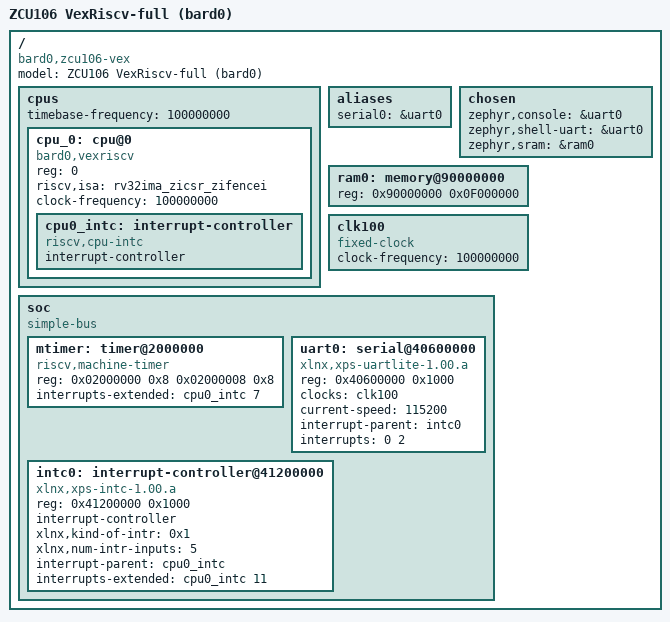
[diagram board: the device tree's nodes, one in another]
// SPDX-License-Identifier: Apache-2.0
// Copyright (c) 2026 Leonardo Capossio - bard0 design
//
// Zephyr DTS for the ZCU106 VexRiscv-full shell (hardware built by
// hardware/scripts/build_zcu106.py --variant vex). Same CPU complex, clock
// (100 MHz) and memory map as the Arty A7 Vex shell; the 256 MiB window at
// 0x9000_0000 is in PS DDR4 instead of DDR3:
//   0x9000_0000  240 MiB, mostly inside the Vex D-cache aperture: Zephyr
//   0x9F00_0000  16 MiB, outside it: DMA descriptors, frame buffers and
//                the host page (the app overlay places them)

/dts-v1/;

/ {
	#address-cells = <1>;
	#size-cells = <1>;
	model = "ZCU106 VexRiscv-full (bard0)";
	compatible = "bard0,zcu106-vex";

	cpus {
		#address-cells = <1>;
		#size-cells = <0>;
		timebase-frequency = <100000000>;

		cpu_0: cpu@0 {
			compatible = "bard0,vexriscv", "riscv";
			device_type = "cpu";
			reg = <0>;
			riscv,isa = "rv32ima_zicsr_zifencei";
			clock-frequency = <100000000>;

			cpu0_intc: interrupt-controller {
				compatible = "riscv,cpu-intc";
				interrupt-controller;
				#interrupt-cells = <1>;
			};
		};
	};

	aliases {
		serial0 = &uart0;
	};

	chosen {
		zephyr,console = &uart0;
		zephyr,shell-uart = &uart0;
		zephyr,sram = &ram0;
	};

	// PS DDR4, 240 MiB usable (0x9000_0000 .. 0x9EFF_FFFF, as on the
	// Arty). fcapz stages the Zephyr image here; the boot ROM at 0x0 jumps
	// in.
	ram0: memory@90000000 {
		device_type = "memory";
		reg = <0x90000000 0x0F000000>;
	};

	clk100: clk100 {
		compatible = "fixed-clock";
		#clock-cells = <0>;
		clock-frequency = <100000000>;
	};

	soc {
		#address-cells = <1>;
		#size-cells = <1>;
		compatible = "simple-bus";
		ranges;

		// riscv_mtimer.v: mtime at +0, mtimecmp at +8
		mtimer: timer@2000000 {
			compatible = "riscv,machine-timer";
			reg = <0x02000000 0x8 0x02000008 0x8>;
			reg-names = "mtime", "mtimecmp";
			interrupts-extended = <&cpu0_intc 7>;
		};

		// AXI UARTLite on the CP2108's PL channel. IRQ 0 on the axi_intc.
		uart0: serial@40600000 {
			compatible = "xlnx,xps-uartlite-1.00.a";
			reg = <0x40600000 0x1000>;
			clocks = <&clk100>;
			current-speed = <115200>;
			interrupt-parent = <&intc0>;
			interrupts = <0 2>;
			status = "okay";
		};

		// AXI INTC, dispatching to VexRiscv's M-mode external interrupt.
		// Inputs: 0 uart0 (edge), 1 PCS/PMA status GPIO, 2 axi_dma mm2s,
		// 3 axi_dma s2mm, 4 emaczero.
		intc0: interrupt-controller@41200000 {
			compatible = "xlnx,xps-intc-1.00.a";
			reg = <0x41200000 0x1000>;
			interrupt-controller;
			#interrupt-cells = <2>;
			xlnx,kind-of-intr = <0x1>;
			xlnx,num-intr-inputs = <5>;
			interrupt-parent = <&cpu0_intc>;
			interrupts-extended = <&cpu0_intc 11>;
		};
	};
};
